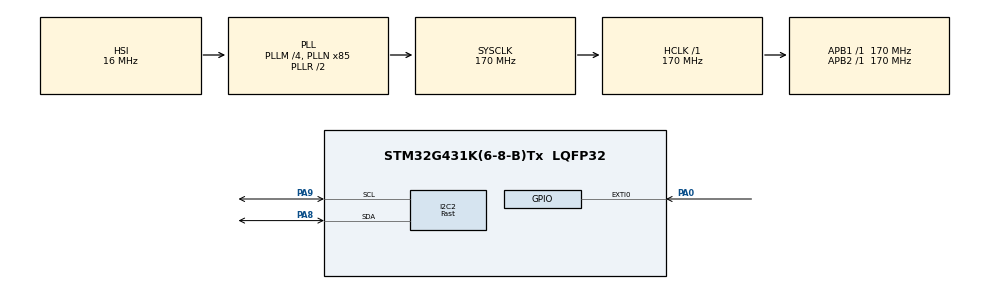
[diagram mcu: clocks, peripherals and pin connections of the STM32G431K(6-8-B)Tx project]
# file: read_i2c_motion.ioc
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ADC1.Channel-0\#ChannelRegularConversion=ADC_CHANNEL_TEMPSENSOR_ADC1
ADC1.ExternalTrigConv=ADC_EXTERNALTRIG_T15_TRGO
ADC1.NbrOfConversionFlag=1
ADC1.OffsetNumber-0\#ChannelRegularConversion=ADC_OFFSET_NONE
ADC1.Rank-0\#ChannelRegularConversion=1
ADC1.SamplingTime-0\#ChannelRegularConversion=ADC_SAMPLETIME_640CYCLES_5
ADC1.master=1
I2C2.CustomTiming=Enabled
I2C2.I2C_Speed_Mode=I2C_Fast
I2C2.Timing=0x40B285C2
Mcu.Family=STM32G4
Mcu.Name=STM32G431K(6-8-B)Tx
Mcu.Package=LQFP32
NUCLEO-G431KB.Bsp_Common_DEMO=true
NUCLEO-G431KB.LD2=true
NUCLEO-G431KB.VCP=true
NVIC.ADC1_2_IRQn=true\:0\:0\:false\:false\:true\:true\:true\:true
NVIC.EXTI0_IRQn=true\:0\:0\:false\:true\:true\:1\:true\:true\:true
NVIC.I2C2_ER_IRQn=true\:0\:0\:false\:true\:true\:3\:true\:true\:true
NVIC.I2C2_EV_IRQn=true\:0\:0\:false\:true\:true\:2\:true\:true\:true
NVIC.PriorityGroup=NVIC_PRIORITYGROUP_4
PA0.GPIO_ModeDefaultEXTI=GPIO_MODE_IT_FALLING
PA0.Signal=GPXTI0
PA13.Mode=Serial_Wire
PA13.Signal=SYS_JTMS-SWDIO
PA14.Mode=Serial_Wire
PA14.Signal=SYS_JTCK-SWCLK
PA2.Signal=USART2_TX
PA3.Signal=USART2_RX
PA8.GPIO_Pu=GPIO_PULLUP
PA8.GPIO_Speed=GPIO_SPEED_FREQ_HIGH
PA8.Mode=I2C
PA8.Signal=I2C2_SDA
PA9.GPIO_Pu=GPIO_PULLUP
PA9.GPIO_Speed=GPIO_SPEED_FREQ_HIGH
PA9.Mode=I2C
PA9.Signal=I2C2_SCL
PF0-OSC_IN.Mode=HSE-External-Oscillator
PF0-OSC_IN.Signal=RCC_OSC_IN
PF1-OSC_OUT.Mode=HSE-External-Oscillator
PF1-OSC_OUT.Signal=RCC_OSC_OUT
ProjectManager.HeapSize=0x200
ProjectManager.StackSize=0x400
ProjectManager.TargetToolchain=STM32CubeIDE
RCC.ADC12Freq_Value=170000000
RCC.AHBFreq_Value=170000000
RCC.APB1Freq_Value=170000000
RCC.APB1TimFreq_Value=170000000
RCC.APB2Freq_Value=170000000
RCC.APB2TimFreq_Value=170000000
RCC.CortexFreq_Value=170000000
RCC.EXTERNAL_CLOCK_VALUE=12288000
RCC.HCLKFreq_Value=170000000
RCC.HSE_VALUE=8000000
RCC.HSI48_VALUE=48000000
RCC.HSI_VALUE=16000000
RCC.LSE_VALUE=32768
RCC.PLLM=RCC_PLLM_DIV4
RCC.PLLN=85
RCC.PREFETCH_ENABLE=1
RCC.SYSCLKFreq_VALUE=170000000
RCC.SYSCLKSource=RCC_SYSCLKSOURCE_PLLCLK
RCC.USBFreq_Value=170000000
RCC.VCOOutputFreq_Value=340000000
VP_ADC1_TempSens_Input.Mode=IN-TempSens
VP_ADC1_Vref_Input.Mode=IN-Vrefint
VP_NUCLEO-G431KB_VS_BSP_COMMON.Mode=COMMON
VP_RTC_VS_RTC_Activate.Mode=RTC_Enabled
VP_SYS_VS_DBSignals.Mode=DisableDeadBatterySignals
VP_SYS_V_PVD_IN.Mode=Mode_PVD_Int
VP_TIM15_VS_ClockSourceINT.Mode=Internal
board=NUCLEO-G431KB

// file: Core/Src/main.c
/* USER CODE BEGIN Header */
/**
  ******************************************************************************
  * @file           : main.c
  * @brief          : Main program body
  ******************************************************************************
  * @attention
  *
  * Copyright (c) 2026 STMicroelectronics.
  * All rights reserved.
  *
  * This software is licensed under terms that can be found in the LICENSE file
  * in the root directory of this software component.
  * If no LICENSE file comes with this software, it is provided AS-IS.
  *
  ******************************************************************************
  */
/* USER CODE END Header */
#include "main.h"

/* USER CODE BEGIN Includes */
#include <string.h>
#include "i2c.h"
#include "gpio.h"
#include "OLED.h"
/* USER CODE END Includes */

/* USER CODE BEGIN PD */
#define LIS3DH_ADDR             0x18<<1  // 7-bit I2C address. If SA0 is pulled high, address is 0x19.
#define LIS3DH_DEVICE_ID        0x33  // Contents of WHO_AM_I register.
#define WHO_AM_I	0x0F
#define OUT_X_L		0x28
#define OUT_ADC1_L	0x08	// ADC channel 1 conversion or temperature sensor data output.

#define CTRL_REG1	0x20
#define CTRL_REG2	0x21
#define CTRL_REG3	0x22
#define CTRL_REG4	0x23
#define CTRL_REG5	0x24

#define INT1_CFG    0x30
#define INT1_SRC    0x31  // r
#define INT1_THS    0x32  // rw
#define INT1_DUR    0x33

#define TEMP_CFG_REG	0x1F

/* USER CODE END PD */

COM_InitTypeDef BspCOMInit;

ADC_HandleTypeDef hadc1;

I2C_HandleTypeDef hi2c2;

RTC_HandleTypeDef hrtc;

TIM_HandleTypeDef htim15;

/* USER CODE BEGIN PV */
// static const uint8_t HUM_ADDR = 0x44 << 1;
// static const uint8_t LIS3DH_ADDR = 0x18 << 1;
// static const uint8_t DISPLAY_ADDR = 0x3C << 1;
// static const uint8_t TEMP_ADDR = 0x48 << 1;
// static const uint8_t BMP280_ADDR 0x77 << 1
// static const uint8_t AHT20_ADDR 0x38 << 1

uint8_t check, data[2], accel_data[6], temp_data[2];

int16_t X_RAW, Y_RAW, Z_RAW, TEMP_RAW;

float Ax, Ay, Az, temperature;

char tx[100];
/* USER CODE END PV */

void SystemClock_Config(void);
static void MX_GPIO_Init(void);
static void MX_I2C2_Init(void);
static void MX_ADC1_Init(void);
static void MX_RTC_Init(void);
static void MX_TIM15_Init(void);
static void MX_NVIC_Init(void);
/* USER CODE BEGIN PFP */
void LIS3DH_write(uint8_t reg_addr, uint8_t value);
void LIS3DH_read_accel(uint8_t reg_addr);
void LIS3DH_init(uint8_t reg_addr);
void LIS3DH_read_temp(uint8_t reg_addr);
/* USER CODE END PFP */

int main(void)
{

  /* MCU Configuration--------------------------------------------------------*/

  /* Reset of all peripherals, Initializes the Flash interface and the Systick. */
  HAL_Init();

  /* Configure the system clock */
  SystemClock_Config();

  /* Initialize all configured peripherals */
  MX_GPIO_Init();
  MX_I2C2_Init();
  MX_ADC1_Init();
  MX_RTC_Init();
  MX_TIM15_Init();

  /* Initialize interrupts */
  MX_NVIC_Init();

  /* Initialize leds */
  BSP_LED_Init(LED_GREEN);

  /* Initialize COM1 port (115200, 8 bits (7-bit data + 1 stop bit), no parity */
  BspCOMInit.BaudRate   = 115200;
  BspCOMInit.WordLength = COM_WORDLENGTH_8B;
  BspCOMInit.StopBits   = COM_STOPBITS_1;
  BspCOMInit.Parity     = COM_PARITY_NONE;
  BspCOMInit.HwFlowCtl  = COM_HWCONTROL_NONE;
  if (BSP_COM_Init(COM1, &BspCOMInit) != BSP_ERROR_NONE)
  {
    Error_Handler();
  }

  /* USER CODE BEGIN BSP */

  /* -- Sample board code to send message over COM1 port ---- */
  printf("Welcome to STM32 world !\n\r");

  /* -- Sample board code to switch on leds ---- */
  BSP_LED_On(LED_GREEN);
  /* USER CODE END BSP */

  /* Infinite loop */
  /* USER CODE BEGIN WHILE */
	LIS3DH_init(0x0F);		//WHO_AM_I (0Fh)
  //Display Initialisation
  HAL_Delay(100);
  OLED_Init(Display);
  HAL_Delay(10);
  OLED_CLS(Display);
  HAL_Delay(10);
  OLED_P8x16Str(Display, 0, 4, "MaKE sOme FuN!;)");
  HAL_Delay(2000);
  OLED_CLS(Display);
  HAL_Delay(10);

  uint8_t int1_status = 0;
  uint8_t alarm_triggered = 0;

  while (1)
  {

/* -- Sample board code to toggle leds ---- */
       BSP_LED_Toggle(LED_GREEN);

    /* USER CODE END WHILE */

    /* USER CODE BEGIN 3 */
		LIS3DH_read_accel(OUT_X_L);		//X-axis acceleration data output.
		LIS3DH_read_temp(OUT_ADC1_L);			//temperature sensor data output.

		X_RAW = (accel_data[1]<<8|accel_data[0]);
		Y_RAW = (accel_data[3]<<8|accel_data[2]);
		Z_RAW = (accel_data[5]<<8|accel_data[4]);

		// Convert into 'mg'
		Ax = ( (float)X_RAW / 64.0f ) *  4.0f;
		Ay = ( (float)Y_RAW / 64.0f ) *  4.0f;
		Az = ( (float)Z_RAW / 64.0f ) *  4.0f;

//		// Convert into 'g'
//		Ax = Ax / 1000.0f;
//		Ay = Ay / 1000.0f;
//		Az = Az / 1000.0f;

		TEMP_RAW = (temp_data[1]<<8|temp_data[0]);
		// Convert into 'celsius',
		temperature = ( ( (float)TEMP_RAW / 64.0f ) / 4.0f ) + 25.0f;
// todo: use aht20 sensor
		 printf("\n");
		 printf("X = %.2f, Y = %.2f, Z = %.2f, temperature = %.2f\r\n", Ax, Ay, Az, temperature);

		 uint8_t reg_addr = 0x31;
		     HAL_I2C_Master_Transmit(&hi2c2, LIS3DH_ADDR, &reg_addr, 1, 1000);
		     HAL_I2C_Master_Receive(&hi2c2, LIS3DH_ADDR, &int1_status, 1, 1000);

		     // Bit 6 (0x40) of INT1_SRC goes HIGH if any configured threshold event happened
		     if (int1_status & 0x40)
		     {
		         alarm_triggered = 1;
		         printf("ALARM TRIGGERED !!! Threshold exceeded!\r\n");
		     }
		     else
		     {
		         alarm_triggered = 0;
		     }

		 uint8_t line = 0;
		 char buf_x[16];
		 char buf_y[16];
		 char buf_z[16];

		 sprintf(buf_x, "X: %.2f  ", Ax);
		 sprintf(buf_y, "Y: %.2f  ", Ay);
		 sprintf(buf_z, "Z: %.2f  ", Az);

		 OLED_P6x8Str(Display, 0, 0, "Sensor values:");

		 OLED_P6x8Str(Display, 0, (line + 1) * 2, buf_x);
		 line++;
		 OLED_P6x8Str(Display, 0, (line + 1) * 2, buf_y);
		 line++;
		 OLED_P6x8Str(Display, 0, (line + 1) * 2, buf_z);

		 if (alarm_triggered)
		     {
		         // Highlight an active warning at the bottom of the screen

			 	 OLED_P6x8Str(Display, 0, (line + 1) * 2, "HIT DETECTED !!");
			 	 HAL_Delay(1000);
		    	 OLED_P6x8Str(Display, 0, (line + 1) * 2, "                ");

		     }

		HAL_Delay(1000);
  }
  /* USER CODE END 3 */
}

void SystemClock_Config(void)
{
  RCC_OscInitTypeDef RCC_OscInitStruct = {0};
  RCC_ClkInitTypeDef RCC_ClkInitStruct = {0};

  /** Configure the main internal regulator output voltage
  */
  HAL_PWREx_ControlVoltageScaling(PWR_REGULATOR_VOLTAGE_SCALE1_BOOST);

  /** Initializes the RCC Oscillators according to the specified parameters
  * in the RCC_OscInitTypeDef structure.
  */
  RCC_OscInitStruct.OscillatorType = RCC_OSCILLATORTYPE_HSI|RCC_OSCILLATORTYPE_LSI;
  RCC_OscInitStruct.HSIState = RCC_HSI_ON;
  RCC_OscInitStruct.HSICalibrationValue = RCC_HSICALIBRATION_DEFAULT;
  RCC_OscInitStruct.LSIState = RCC_LSI_ON;
  RCC_OscInitStruct.PLL.PLLState = RCC_PLL_ON;
  RCC_OscInitStruct.PLL.PLLSource = RCC_PLLSOURCE_HSI;
  RCC_OscInitStruct.PLL.PLLM = RCC_PLLM_DIV4;
  RCC_OscInitStruct.PLL.PLLN = 85;
  RCC_OscInitStruct.PLL.PLLP = RCC_PLLP_DIV2;
  RCC_OscInitStruct.PLL.PLLQ = RCC_PLLQ_DIV2;
  RCC_OscInitStruct.PLL.PLLR = RCC_PLLR_DIV2;
  if (HAL_RCC_OscConfig(&RCC_OscInitStruct) != HAL_OK)
  {
    Error_Handler();
  }

  /** Initializes the CPU, AHB and APB buses clocks
  */
  RCC_ClkInitStruct.ClockType = RCC_CLOCKTYPE_HCLK|RCC_CLOCKTYPE_SYSCLK
                              |RCC_CLOCKTYPE_PCLK1|RCC_CLOCKTYPE_PCLK2;
  RCC_ClkInitStruct.SYSCLKSource = RCC_SYSCLKSOURCE_PLLCLK;
  RCC_ClkInitStruct.AHBCLKDivider = RCC_SYSCLK_DIV1;
  RCC_ClkInitStruct.APB1CLKDivider = RCC_HCLK_DIV1;
  RCC_ClkInitStruct.APB2CLKDivider = RCC_HCLK_DIV1;

  if (HAL_RCC_ClockConfig(&RCC_ClkInitStruct, FLASH_LATENCY_4) != HAL_OK)
  {
    Error_Handler();
  }
}

/**
  * @brief NVIC Configuration.
  * @retval None
  */
static void MX_NVIC_Init(void)
{
  /* EXTI0_IRQn interrupt configuration */
  HAL_NVIC_SetPriority(EXTI0_IRQn, 0, 0);
  HAL_NVIC_EnableIRQ(EXTI0_IRQn);
  /* I2C2_EV_IRQn interrupt configuration */
  HAL_NVIC_SetPriority(I2C2_EV_IRQn, 0, 0);
  HAL_NVIC_EnableIRQ(I2C2_EV_IRQn);
  /* I2C2_ER_IRQn interrupt configuration */
  HAL_NVIC_SetPriority(I2C2_ER_IRQn, 0, 0);
  HAL_NVIC_EnableIRQ(I2C2_ER_IRQn);
}

static void MX_ADC1_Init(void)
{

  ADC_MultiModeTypeDef multimode = {0};
  ADC_ChannelConfTypeDef sConfig = {0};

  /** Common config
  */
  hadc1.Instance = ADC1;
  hadc1.Init.ClockPrescaler = ADC_CLOCK_SYNC_PCLK_DIV4;
  hadc1.Init.Resolution = ADC_RESOLUTION_12B;
  hadc1.Init.DataAlign = ADC_DATAALIGN_RIGHT;
  hadc1.Init.GainCompensation = 0;
  hadc1.Init.ScanConvMode = ADC_SCAN_DISABLE;
  hadc1.Init.EOCSelection = ADC_EOC_SINGLE_CONV;
  hadc1.Init.LowPowerAutoWait = DISABLE;
  hadc1.Init.ContinuousConvMode = DISABLE;
  hadc1.Init.NbrOfConversion = 1;
  hadc1.Init.DiscontinuousConvMode = DISABLE;
  hadc1.Init.ExternalTrigConv = ADC_EXTERNALTRIG_T15_TRGO;
  hadc1.Init.ExternalTrigConvEdge = ADC_EXTERNALTRIGCONVEDGE_RISING;
  hadc1.Init.DMAContinuousRequests = DISABLE;
  hadc1.Init.Overrun = ADC_OVR_DATA_PRESERVED;
  hadc1.Init.OversamplingMode = DISABLE;
  if (HAL_ADC_Init(&hadc1) != HAL_OK)
  {
    Error_Handler();
  }

  /** Configure the ADC multi-mode
  */
  multimode.Mode = ADC_MODE_INDEPENDENT;
  if (HAL_ADCEx_MultiModeConfigChannel(&hadc1, &multimode) != HAL_OK)
  {
    Error_Handler();
  }

  /** Configure Regular Channel
  */
  sConfig.Channel = ADC_CHANNEL_TEMPSENSOR_ADC1;
  sConfig.Rank = ADC_REGULAR_RANK_1;
  sConfig.SamplingTime = ADC_SAMPLETIME_640CYCLES_5;
  sConfig.SingleDiff = ADC_SINGLE_ENDED;
  sConfig.OffsetNumber = ADC_OFFSET_NONE;
  sConfig.Offset = 0;
  if (HAL_ADC_ConfigChannel(&hadc1, &sConfig) != HAL_OK)
  {
    Error_Handler();
  }

}

static void MX_I2C2_Init(void)
{

  hi2c2.Instance = I2C2;
  hi2c2.Init.Timing = 0x40B285C2;
  hi2c2.Init.OwnAddress1 = 0;
  hi2c2.Init.AddressingMode = I2C_ADDRESSINGMODE_7BIT;
  hi2c2.Init.DualAddressMode = I2C_DUALADDRESS_DISABLE;
  hi2c2.Init.OwnAddress2 = 0;
  hi2c2.Init.OwnAddress2Masks = I2C_OA2_NOMASK;
  hi2c2.Init.GeneralCallMode = I2C_GENERALCALL_DISABLE;
  hi2c2.Init.NoStretchMode = I2C_NOSTRETCH_DISABLE;
  if (HAL_I2C_Init(&hi2c2) != HAL_OK)
  {
    Error_Handler();
  }

  /** Configure Analogue filter
  */
  if (HAL_I2CEx_ConfigAnalogFilter(&hi2c2, I2C_ANALOGFILTER_ENABLE) != HAL_OK)
  {
    Error_Handler();
  }

  /** Configure Digital filter
  */
  if (HAL_I2CEx_ConfigDigitalFilter(&hi2c2, 0) != HAL_OK)
  {
    Error_Handler();
  }

}

static void MX_RTC_Init(void)
{

  /** Initialize RTC Only
  */
  hrtc.Instance = RTC;
  hrtc.Init.HourFormat = RTC_HOURFORMAT_24;
  hrtc.Init.AsynchPrediv = 127;
  hrtc.Init.SynchPrediv = 255;
  hrtc.Init.OutPut = RTC_OUTPUT_DISABLE;
  hrtc.Init.OutPutRemap = RTC_OUTPUT_REMAP_NONE;
  hrtc.Init.OutPutPolarity = RTC_OUTPUT_POLARITY_HIGH;
  hrtc.Init.OutPutType = RTC_OUTPUT_TYPE_OPENDRAIN;
  hrtc.Init.OutPutPullUp = RTC_OUTPUT_PULLUP_NONE;
  if (HAL_RTC_Init(&hrtc) != HAL_OK)
  {
    Error_Handler();
  }

}

static void MX_TIM15_Init(void)
{

  TIM_ClockConfigTypeDef sClockSourceConfig = {0};
  TIM_MasterConfigTypeDef sMasterConfig = {0};

  htim15.Instance = TIM15;
  htim15.Init.Prescaler = 0;
  htim15.Init.CounterMode = TIM_COUNTERMODE_UP;
  htim15.Init.Period = 65535;
  htim15.Init.ClockDivision = TIM_CLOCKDIVISION_DIV1;
  htim15.Init.RepetitionCounter = 0;
  htim15.Init.AutoReloadPreload = TIM_AUTORELOAD_PRELOAD_DISABLE;
  if (HAL_TIM_Base_Init(&htim15) != HAL_OK)
  {
    Error_Handler();
  }
  sClockSourceConfig.ClockSource = TIM_CLOCKSOURCE_INTERNAL;
  if (HAL_TIM_ConfigClockSource(&htim15, &sClockSourceConfig) != HAL_OK)
  {
    Error_Handler();
  }
  sMasterConfig.MasterOutputTrigger = TIM_TRGO_RESET;
  sMasterConfig.MasterSlaveMode = TIM_MASTERSLAVEMODE_DISABLE;
  if (HAL_TIMEx_MasterConfigSynchronization(&htim15, &sMasterConfig) != HAL_OK)
  {
    Error_Handler();
  }

}

static void MX_GPIO_Init(void)
{
  GPIO_InitTypeDef GPIO_InitStruct = {0};

  /* GPIO Ports Clock Enable */
  __HAL_RCC_GPIOF_CLK_ENABLE();
  __HAL_RCC_GPIOA_CLK_ENABLE();

  /*Configure GPIO pin : PA0 */
  GPIO_InitStruct.Pin = GPIO_PIN_0;
  GPIO_InitStruct.Mode = GPIO_MODE_IT_FALLING;
  GPIO_InitStruct.Pull = GPIO_NOPULL;
  HAL_GPIO_Init(GPIOA, &GPIO_InitStruct);

}

/* USER CODE BEGIN 4 */

void LIS3DH_write(uint8_t reg_addr, uint8_t value)
{
	data[0] = reg_addr;
	data[1] = value;

	while(HAL_I2C_Master_Transmit(&hi2c2, LIS3DH_ADDR, data, 2, 1000)!= HAL_OK)
	{
		if(HAL_I2C_GetError(&hi2c2) != HAL_I2C_ERROR_AF)		//Acknowledge
		{
			Error_Handler();
		}
	}
}

void LIS3DH_read_accel(uint8_t reg_addr)
{
	reg_addr |= 0x80;		//multibyte read enabled

	while(HAL_I2C_Master_Transmit(&hi2c2, LIS3DH_ADDR, &reg_addr, 1, 1000) != HAL_OK)
	{
		if(HAL_I2C_GetError(&hi2c2) != HAL_I2C_ERROR_AF)		//Acknowledge
		{
			Error_Handler();
		}
	}
	while(HAL_I2C_Master_Receive(&hi2c2, LIS3DH_ADDR, accel_data, 6, 1000) != HAL_OK)
	{
		if(HAL_I2C_GetError(&hi2c2) != HAL_I2C_ERROR_AF)		//Acknowledge
		{
			Error_Handler();
		}
	}
}

void LIS3DH_init(uint8_t reg_addr)
{
	while(HAL_I2C_Master_Transmit(&hi2c2, LIS3DH_ADDR, &reg_addr, 1, 1000) != HAL_OK)
	{
		if(HAL_I2C_GetError(&hi2c2) != HAL_I2C_ERROR_AF)		//Acknowledge
		{
			Error_Handler();
		}
	}
	while(HAL_I2C_Master_Receive(&hi2c2, LIS3DH_ADDR, &check, 1, 1000) != HAL_OK)
	{
		if(HAL_I2C_GetError(&hi2c2) != HAL_I2C_ERROR_AF)		//Acknowledge
		{
			Error_Handler();
		}
	}
	if(check == LIS3DH_DEVICE_ID)
	{
//
//		LIS3DH_write(CTRL_REG5, 0x80);		//Reboot memory content.
//		HAL_Delay(100);
//		LIS3DH_write(CTRL_REG1, 0x00);		//Power-down.
//		HAL_Delay(100);
//		LIS3DH_write(CTRL_REG1, 0x77);		//Power-up normal mode, 400Hz, XYZ-axis enabled
//		HAL_Delay(100);
//		LIS3DH_write(CTRL_REG4, 0x80);		//0x00-> 2g, 0x10-> 4g, 0x20-> 8g, 0x30-> 16g and high-resolution disabled.
//		HAL_Delay(100);
//		LIS3DH_write(TEMP_CFG_REG, 0x08);		//Temperature sensor and ADC enabled.
//		HAL_Delay(100);

//		Startup sequence
		// 1. Reboot memory content to ensure a clean slate
		LIS3DH_write(CTRL_REG5, 0x80);
		HAL_Delay(20);

		// 2. Set Full Scale to ±2g and enable Block Data Update (BDU)
		LIS3DH_write(CTRL_REG4, 0x80);        // CTRL_REG4 = 0x80 (1 LSB threshold = 16mg)

		// 3. Route the INT1 IA1 (Interrupt Activity 1) signal to the physical INT1 pin
		LIS3DH_write(CTRL_REG3, 0x40);        // CTRL_REG3 = 0x40 (Enables I1_IA1)

		// 4. Set the threshold (250mg / 16mg = 16 = 0x10)
		LIS3DH_write(INT1_THS, 0x10);        // INT1_THS = 0x10

		// 5. Set the minimum duration the event must last to trigger (0 = triggers instantly)
		LIS3DH_write(INT1_DUR, 0x00);        // INT1_DURATION = 0x00

		// 6. Configure the event condition: High event (OR combination) on X, Y, or Z axes
		LIS3DH_write(INT1_CFG, 0x2A);        // INT1_CFG = 0x2A (00101010b -> ZHIE, YHIE, XHIE enabled)

		// 7. Latch the interrupt on the INT1 pin until read INT1_SRC
		 LIS3DH_write(CTRL_REG5, 0x08);     // CTRL_REG5 = 0x08 (LIR1 = 1)

		 LIS3DH_write(CTRL_REG2, 0x01);  // High-pass filter enabled for INT1
		// 8. Turn the sensor on. (Power-up normal mode, 400Hz, XYZ enabled)
		LIS3DH_write(CTRL_REG1, 0x77);        // CTRL_REG1 = 0x77
		HAL_Delay(20);
	}
}

void LIS3DH_read_temp(uint8_t reg_addr)
{
	reg_addr |= 0x80;		//multibyte read enabled

	while(HAL_I2C_Master_Transmit(&hi2c2, LIS3DH_ADDR, &reg_addr, 1, 1000) != HAL_OK)
	{
		if(HAL_I2C_GetError(&hi2c2) != HAL_I2C_ERROR_AF)		//Acknowledge
		{
			Error_Handler();
		}
	}
	while(HAL_I2C_Master_Receive(&hi2c2, LIS3DH_ADDR, temp_data, 2, 1000) != HAL_OK)
	{
		if(HAL_I2C_GetError(&hi2c2) != HAL_I2C_ERROR_AF)		//Acknowledge
		{
			Error_Handler();
		}
	}
}

/* USER CODE END 4 */

/* USER CODE BEGIN Header */
/**
  ******************************************************************************
  * @file           : main.c
  * @brief          : Main program body
  ******************************************************************************
  * @attention
  *
  * Copyright (c) 2026 STMicroelectronics.
  * All rights reserved.
  *
  * This software is licensed under terms that can be found in the LICENSE file
  * in the root directory of this software component.
  * If no LICENSE file comes with this software, it is provided AS-IS.
  *
  ******************************************************************************
  */
/* USER CODE END Header */

void Error_Handler(void)
{
  __disable_irq();
  while (1)
  {
  }
}
